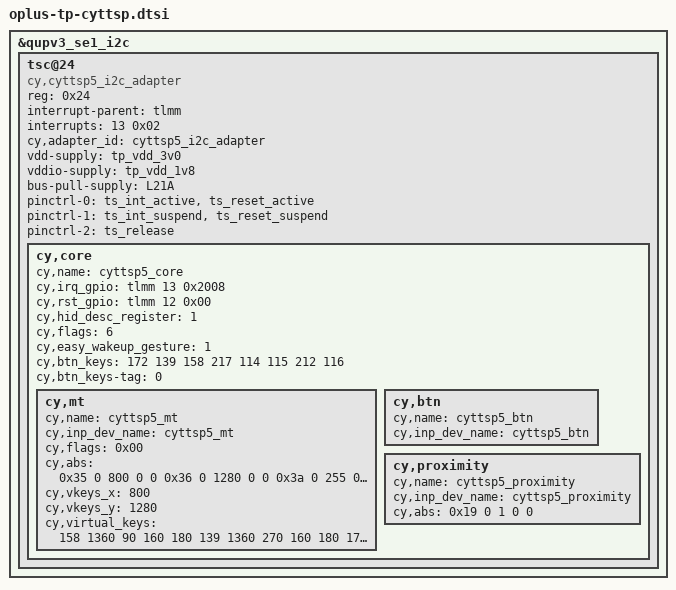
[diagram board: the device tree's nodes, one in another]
&qupv3_se1_i2c {
	/delete-node/ tsc@24;
	tsc@24 {
		compatible = "cy,cyttsp5_i2c_adapter";
		reg = <0x24>;

		interrupt-parent = <&tlmm>;
		interrupts = <13 0x02>;
		cy,adapter_id = "cyttsp5_i2c_adapter";
		vdd-supply = <&tp_vdd_3v0>;
		vddio-supply = <&tp_vdd_1v8>;
		bus-pull-supply = <&L21A>;

		/* pins used by touchscreen */
		pinctrl-names = "pmx_ts_active", "pmx_ts_suspend",
				"pmx_ts_release";
		pinctrl-0 = <&ts_int_active &ts_reset_active>;
		pinctrl-1 = <&ts_int_suspend &ts_reset_suspend>;
		pinctrl-2 = <&ts_release>;

		cy,core {
			cy,name = "cyttsp5_core";
			cy,irq_gpio = <&tlmm 13 0x2008>;
			cy,rst_gpio = <&tlmm 12 0x00>;
			cy,hid_desc_register = <1>;
			/* CY_CORE_FLAG_RESTORE_PARAMETERS, CY_CORE_FLAG_POWEROFF_ON_SLEEP */
			cy,flags = <6>;
			/* CY_CORE_EWG_NONE */
			cy,easy_wakeup_gesture = <1>;

			cy,btn_keys = <172 /* KEY_HOMEPAGE */
			               /* previously was KEY_HOME, new Android versions use KEY_HOMEPAGE */
			               139 /* KEY_MENU */
			               158 /* KEY_BACK */
			               217 /* KEY_SEARCH */
			               114 /* KEY_VOLUMEDOWN */
			               115 /* KEY_VOLUMEUP */
			               212 /* KEY_CAMERA */
			               116>; /* KEY_POWER */
			cy,btn_keys-tag = <0>;

			cy,mt {
				cy,name = "cyttsp5_mt";

				cy,inp_dev_name = "cyttsp5_mt";

				/* CY_MT_FLAG_FLIP */
				cy,flags = <0x00>;

				cy,abs = <
					/* ABS_MT_POSITION_X, CY_ABS_MIN_X, CY_ABS_MAX_X, 0, 0 */
					0x35 0 800 0 0
					/* ABS_MT_POSITION_Y, CY_ABS_MIN_Y, CY_ABS_MAX_Y, 0, 0 */
					0x36 0 1280 0 0
					/* ABS_MT_PRESSURE, CY_ABS_MIN_P, CY_ABS_MAX_P, 0, 0 */
					0x3a 0 255 0 0
					/* CY_IGNORE_VALUE, CY_ABS_MIN_W, CY_ABS_MAX_W, 0, 0 */
					0xffff 0 255 0 0
					/* ABS_MT_TRACKING_ID, CY_ABS_MIN_T, CY_ABS_MAX_T, 0, 0 */
					0x39 0 15 0 0
					/* ABS_MT_TOUCH_MAJOR, 0, 255, 0, 0 */
					0x30 0 255 0 0
					/* ABS_MT_TOUCH_MINOR, 0, 255, 0, 0 */
					0x31 0 255 0 0
					/* ABS_MT_ORIENTATION, -127, 127, 0, 0 */
					0x34 0xffffff81 127 0 0
					/* ABS_MT_TOOL_TYPE, 0, MT_TOOL_MAX, 0, 0 */
					0x37 0 1 0 0
					/* ABS_DISTANCE, 0, 255, 0, 0 */
					0x19 0 255 0 0
				>;

				cy,vkeys_x = <800>;
				cy,vkeys_y = <1280>;

				/* KeyCode CenterX CenterY Width Height */
				cy,virtual_keys = <
					/* KEY_BACK */
					158 1360 90 160 180
					/* KEY_MENU */
					139 1360 270 160 180
					/* KEY_HOMEPAGE */
					172 1360 450 160 180
					/* KEY SEARCH */
					217 1360 630 160 180
				>;
			};

			cy,btn {
				cy,name = "cyttsp5_btn";

				cy,inp_dev_name = "cyttsp5_btn";
			};

			cy,proximity {
				cy,name = "cyttsp5_proximity";

				cy,inp_dev_name = "cyttsp5_proximity";
				cy,abs =
					/* ABS_DISTANCE, CY_PROXIMITY_MIN_VAL, CY_PROXIMITY_MAX_VAL, 0, 0 */
					<0x19 0 1 0 0>;
			};
		};
	};

};

